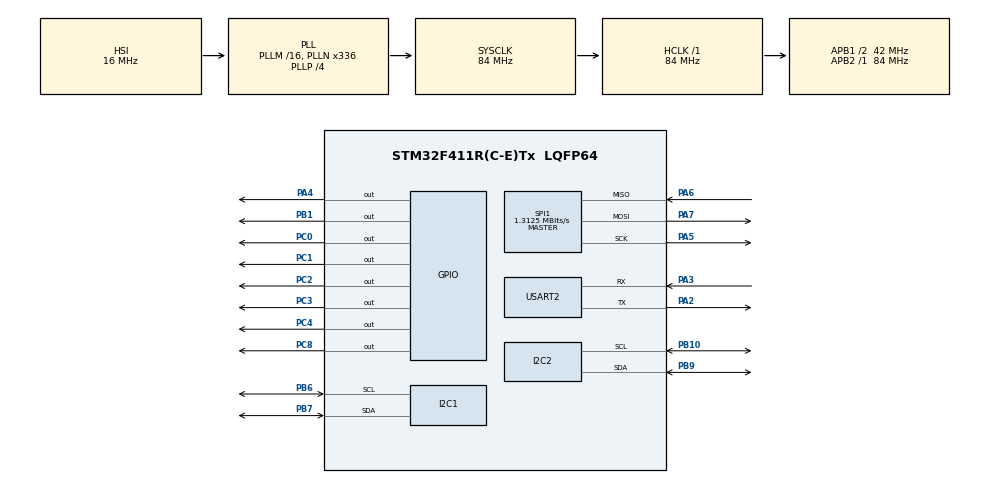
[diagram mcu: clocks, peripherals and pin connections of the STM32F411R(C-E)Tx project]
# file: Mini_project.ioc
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I2C1.NoStretchMode=I2C_NOSTRETCH_DISABLE
Mcu.Family=STM32F4
Mcu.Name=STM32F411R(C-E)Tx
Mcu.Package=LQFP64
NVIC.PriorityGroup=NVIC_PRIORITYGROUP_0
PA2.Mode=Asynchronous
PA2.Signal=USART2_TX
PA3.Mode=Asynchronous
PA3.Signal=USART2_RX
PA4.GPIO_PuPd=GPIO_PULLUP
PA4.Signal=GPIO_Output
PA5.Mode=Full_Duplex_Master
PA5.Signal=SPI1_SCK
PA6.Mode=Full_Duplex_Master
PA6.Signal=SPI1_MISO
PA7.Mode=Full_Duplex_Master
PA7.Signal=SPI1_MOSI
PB1.Signal=GPIO_Output
PB10.Mode=I2C
PB10.Signal=I2C2_SCL
PB3.GPIO_Label=SWO
PB3.Signal=SYS_JTDO-SWO
PB6.GPIO_Pu=GPIO_PULLUP
PB6.Mode=I2C
PB6.Signal=I2C1_SCL
PB7.GPIO_Pu=GPIO_PULLUP
PB7.Mode=I2C
PB7.Signal=I2C1_SDA
PB9.Mode=I2C
PB9.Signal=I2C2_SDA
PC0.Signal=GPIO_Output
PC1.Signal=GPIO_Output
PC2.Signal=GPIO_Output
PC3.Signal=GPIO_Output
PC4.Signal=GPIO_Output
PC8.Signal=GPIO_Output
PH0\ -\ OSC_IN.Mode=HSE-External-Oscillator
PH0\ -\ OSC_IN.Signal=RCC_OSC_IN
PH1\ -\ OSC_OUT.Mode=HSE-External-Oscillator
PH1\ -\ OSC_OUT.Signal=RCC_OSC_OUT
ProjectManager.HeapSize=0x200
ProjectManager.StackSize=0x400
ProjectManager.TargetToolchain=STM32CubeIDE
RCC.48MHZClocksFreq_Value=84000000
RCC.AHBFreq_Value=84000000
RCC.APB1CLKDivider=RCC_HCLK_DIV2
RCC.APB1Freq_Value=42000000
RCC.APB1TimFreq_Value=84000000
RCC.APB2Freq_Value=84000000
RCC.APB2TimFreq_Value=84000000
RCC.CortexFreq_Value=84000000
RCC.FLatency-AdvancedSettings=FLASH_LATENCY_2
RCC.HCLKFreq_Value=84000000
RCC.HSE_VALUE=8000000
RCC.HSI_VALUE=16000000
RCC.LSE_VALUE=32768
RCC.PLLN=336
RCC.PLLP=RCC_PLLP_DIV4
RCC.SYSCLKFreq_VALUE=84000000
RCC.SYSCLKSource=RCC_SYSCLKSOURCE_PLLCLK
RCC.VCOOutputFreq_Value=336000000
SPI1.BaudRatePrescaler=SPI_BAUDRATEPRESCALER_64
SPI1.CalculateBaudRate=1.3125 MBits/s
SPI1.Direction=SPI_DIRECTION_2LINES
SPI1.Mode=SPI_MODE_MASTER
SPI1.VirtualType=VM_MASTER
USART2.VirtualMode=VM_ASYNC
board=NUCLEO-F411RE

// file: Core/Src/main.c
/* USER CODE BEGIN Header */
/**
  ******************************************************************************
  * @file           : main.c
  * @brief          : Main program body
  ******************************************************************************
  */
/* USER CODE END Header */
#include "main.h"
#include "i2c.h"
#include "spi.h"
#include "usart.h"
#include "gpio.h"

/* USER CODE BEGIN Includes */

extern I2C_HandleTypeDef hi2c2;
extern UART_HandleTypeDef huart2;

/* USER CODE END Includes */

void SystemClock_Config(void);

int main(void)
{

  /* MCU Configuration--------------------------------------------------------*/

  /* Reset of all peripherals, Initializes the Flash interface and the Systick. */
  HAL_Init();

  /* Configure the system clock */
  SystemClock_Config();

  /* Initialize all configured peripherals */
  MX_GPIO_Init();
  MX_SPI1_Init();
  MX_USART2_UART_Init();
  MX_I2C1_Init();
  MX_I2C2_Init();

  /* Infinite loop */
  while (1)
  {

  }
}

void SystemClock_Config(void)
{
  RCC_OscInitTypeDef RCC_OscInitStruct = {0};
  RCC_ClkInitTypeDef RCC_ClkInitStruct = {0};

  /** Configure the main internal regulator output voltage
  */
  __HAL_RCC_PWR_CLK_ENABLE();
  __HAL_PWR_VOLTAGESCALING_CONFIG(PWR_REGULATOR_VOLTAGE_SCALE1);

  /** Initializes the RCC Oscillators according to the specified parameters
  * in the RCC_OscInitTypeDef structure.
  */
  RCC_OscInitStruct.OscillatorType = RCC_OSCILLATORTYPE_HSI;
  RCC_OscInitStruct.HSIState = RCC_HSI_ON;
  RCC_OscInitStruct.HSICalibrationValue = RCC_HSICALIBRATION_DEFAULT;
  RCC_OscInitStruct.PLL.PLLState = RCC_PLL_ON;
  RCC_OscInitStruct.PLL.PLLSource = RCC_PLLSOURCE_HSI;
  RCC_OscInitStruct.PLL.PLLM = 16;
  RCC_OscInitStruct.PLL.PLLN = 336;
  RCC_OscInitStruct.PLL.PLLP = RCC_PLLP_DIV4;
  RCC_OscInitStruct.PLL.PLLQ = 4;
  if (HAL_RCC_OscConfig(&RCC_OscInitStruct) != HAL_OK)
  {
    Error_Handler();
  }

  /** Initializes the CPU, AHB and APB buses clocks
  */
  RCC_ClkInitStruct.ClockType = RCC_CLOCKTYPE_HCLK|RCC_CLOCKTYPE_SYSCLK
                              |RCC_CLOCKTYPE_PCLK1|RCC_CLOCKTYPE_PCLK2;
  RCC_ClkInitStruct.SYSCLKSource = RCC_SYSCLKSOURCE_PLLCLK;
  RCC_ClkInitStruct.AHBCLKDivider = RCC_SYSCLK_DIV1;
  RCC_ClkInitStruct.APB1CLKDivider = RCC_HCLK_DIV2;
  RCC_ClkInitStruct.APB2CLKDivider = RCC_HCLK_DIV1;

  if (HAL_RCC_ClockConfig(&RCC_ClkInitStruct, FLASH_LATENCY_2) != HAL_OK)
  {
    Error_Handler();
  }
}

void Error_Handler(void)
{
  __disable_irq();
  while (1)
  {
  }
}
